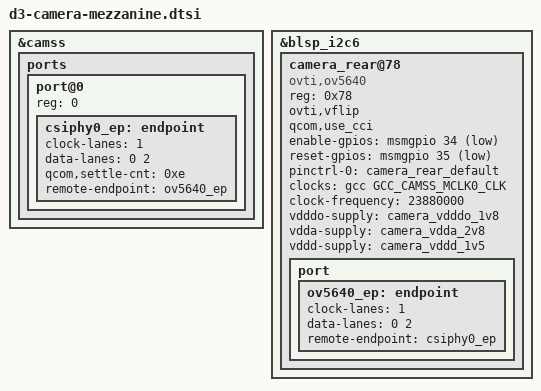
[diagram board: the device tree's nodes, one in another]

&camss {
	ports {
		port@0 {
			reg = <0>;
			csiphy0_ep: endpoint {
				clock-lanes = <1>;
				data-lanes = <0 2>;
				qcom,settle-cnt = <0xe>;
				remote-endpoint = <&ov5640_ep>;
			};
		};
		/* The camera driver requires all listed ports to have attached devices to bind them
		   Uncomment this section and the camera_front device to enable the second camera.
		port@1 {
			reg = <1>;
			csiphy1_ep: endpoint {
				clock-lanes = <1>;
				data-lanes = <0 2>;
				qcom,settle-cnt = <0xe>;
				remote-endpoint = <&ov564_2_ep>;
			};
		};
		*/
	};
};

&blsp_i2c6 {
	status = "ok";

	camera_rear@78 {
		// This port isn't really connected to I2C-6
		// This is a hack until CCI driver is a full i2c driver.
		// The device connections listed are for port J3 - MIPI CSI0
		compatible = "ovti,ov5640";
		reg = <0x78>;

		ovti,vflip;
		qcom,use_cci;
		enable-gpios = <&msmgpio 34 GPIO_ACTIVE_LOW>;
		reset-gpios = <&msmgpio 35 GPIO_ACTIVE_LOW>;
		pinctrl-names = "default";
		pinctrl-0 = <&camera_rear_default>;

		clocks = <&gcc GCC_CAMSS_MCLK0_CLK>;
		clock-names = "xclk";
		clock-frequency = <23880000>;

		vdddo-supply = <&camera_vdddo_1v8>;
		vdda-supply = <&camera_vdda_2v8>;
		vddd-supply = <&camera_vddd_1v5>;

		port {
			ov5640_ep: endpoint {
				clock-lanes = <1>;
				data-lanes = <0 2>;
				remote-endpoint = <&csiphy0_ep>;
			};
		};
	};

	/* The camera driver requires all listed ports to have attached devices to bind them
	   Uncomment this section and Camss->port@1 to enable the second camera.
	camera_front@74 {
		// The device connections listed are for port J4 - MIPI CSI1
		compatible = "ovti,ov5640";
		reg = <0x74>;
		ovti,hflip;

		enable-gpios = <&msmgpio 33 GPIO_ACTIVE_LOW>;
		reset-gpios = <&msmgpio 28 GPIO_ACTIVE_LOW>;
		pinctrl-names = "default";
		pinctrl-0 = <&camera_front_default>;

		clocks = <&gcc GCC_CAMSS_MCLK1_CLK>;
		clock-names = "xclk";
		clock-frequency = <23880000>;

		vdddo-supply = <&camera_vdddo_1v8>;
		vdda-supply = <&camera_vdda_2v8>;
		vddd-supply = <&camera_vddd_1v5>;

		port {
			ov564_2_ep: endpoint {
				clock-lanes = <1>;
				data-lanes = <0 2>;
				remote-endpoint = <&csiphy1_ep>;
			};
		};
	};
	*/
};
